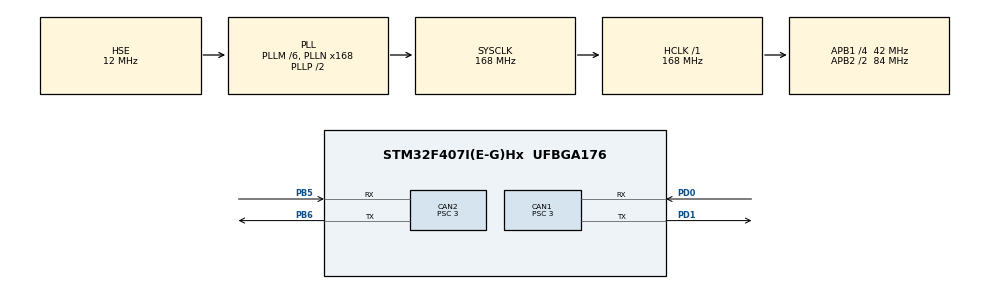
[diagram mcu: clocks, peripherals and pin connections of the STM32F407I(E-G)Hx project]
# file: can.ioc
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CAN1.BS1=CAN_BS1_10TQ
CAN1.BS2=CAN_BS2_3TQ
CAN1.CalculateBaudRate=1000000
CAN1.CalculateTimeQuantum=71.42857142857143
CAN1.Prescaler=3
CAN2.BS1=CAN_BS1_10TQ
CAN2.BS2=CAN_BS2_3TQ
CAN2.CalculateBaudRate=1000000
CAN2.CalculateTimeQuantum=71.42857142857143
CAN2.Prescaler=3
FREERTOS.Tasks01=defaultTask,0,128,StartDefaultTask,Default,NULL,Dynamic,NULL,NULL;CHASSIS_TASK,0,512,Chassis_Task,Default,NULL,Dynamic,NULL,NULL;XY,0,128,xy,Default,NULL,Dynamic,NULL,NULL;TD_TASK,0,128,TD_task,Default,NULL,Dynamic,NULL,NULL
Mcu.Family=STM32F4
Mcu.Name=STM32F407I(E-G)Hx
Mcu.Package=UFBGA176
NVIC.CAN1_RX0_IRQn=true\:5\:0\:false\:false\:true\:true\:true\:true\:true
NVIC.CAN1_TX_IRQn=true\:5\:0\:false\:false\:true\:true\:true\:true\:true
NVIC.CAN2_RX0_IRQn=true\:5\:0\:false\:false\:true\:true\:true\:true\:true
NVIC.CAN2_TX_IRQn=true\:5\:0\:false\:false\:true\:true\:true\:true\:true
NVIC.PriorityGroup=NVIC_PRIORITYGROUP_4
PA13.Mode=Serial_Wire
PA13.Signal=SYS_JTMS-SWDIO
PA14.Mode=Serial_Wire
PA14.Signal=SYS_JTCK-SWCLK
PB5.Mode=CAN_Activate
PB5.Signal=CAN2_RX
PB6.Mode=CAN_Activate
PB6.Signal=CAN2_TX
PD0.Mode=CAN_Activate
PD0.Signal=CAN1_RX
PD1.Mode=CAN_Activate
PD1.Signal=CAN1_TX
PH0-OSC_IN.Mode=HSE-External-Oscillator
PH0-OSC_IN.Signal=RCC_OSC_IN
PH1-OSC_OUT.Mode=HSE-External-Oscillator
PH1-OSC_OUT.Signal=RCC_OSC_OUT
ProjectManager.HeapSize=0x200
ProjectManager.StackSize=0x400
ProjectManager.TargetToolchain=MDK-ARM V5
RCC.48MHZClocksFreq_Value=84000000
RCC.AHBFreq_Value=168000000
RCC.APB1CLKDivider=RCC_HCLK_DIV4
RCC.APB1Freq_Value=42000000
RCC.APB1TimFreq_Value=84000000
RCC.APB2CLKDivider=RCC_HCLK_DIV2
RCC.APB2Freq_Value=84000000
RCC.APB2TimFreq_Value=168000000
RCC.CortexFreq_Value=168000000
RCC.HCLKFreq_Value=168000000
RCC.HSE_VALUE=12000000
RCC.HSI_VALUE=16000000
RCC.LSE_VALUE=32768
RCC.PLLM=6
RCC.PLLN=168
RCC.PLLSourceVirtual=RCC_PLLSOURCE_HSE
RCC.SYSCLKFreq_VALUE=168000000
RCC.SYSCLKSource=RCC_SYSCLKSOURCE_PLLCLK
RCC.VCOOutputFreq_Value=336000000
VP_FREERTOS_VS_CMSIS_V1.Mode=CMSIS_V1
board=custom

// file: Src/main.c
/* USER CODE BEGIN Header */
/**
  ******************************************************************************
  * @file           : main.c
  * @brief          : Main program body
  ******************************************************************************
  * @attention
  *
  * <h2><center>&copy; Copyright (c) 2019 STMicroelectronics.
  * All rights reserved.</center></h2>
  *
  * This software component is licensed by ST under BSD 3-Clause license,
  * the "License"; You may not use this file except in compliance with the
  * License. You may obtain a copy of the License at:
  *                        opensource.org/licenses/BSD-3-Clause
  *
  ******************************************************************************
  */
/* USER CODE END Header */
#include "main.h"
#include "cmsis_os.h"
#include "can.h"
#include "gpio.h"

/* USER CODE BEGIN Includes */
#include "bsp_can.h"
#include "CAN_receive.h"
/* USER CODE END Includes */

void SystemClock_Config(void);
void MX_FREERTOS_Init(void);

int main(void)
{

  /* MCU Configuration--------------------------------------------------------*/

  /* Reset of all peripherals, Initializes the Flash interface and the Systick. */
  HAL_Init();

  /* Configure the system clock */
  SystemClock_Config();

  /* Initialize all configured peripherals */
  MX_GPIO_Init();
  MX_CAN1_Init();
  MX_CAN2_Init();
  /* USER CODE BEGIN 2 */
    can_filter_init();
  /* USER CODE END 2 */

  /* Call init function for freertos objects (in cmsis_os2.c) */
  MX_FREERTOS_Init();

  /* Start scheduler */
  osKernelStart();

  /* We should never get here as control is now taken by the scheduler */

  /* Infinite loop */
  while (1)
  {

  }
}

void SystemClock_Config(void)
{
  RCC_OscInitTypeDef RCC_OscInitStruct = {0};
  RCC_ClkInitTypeDef RCC_ClkInitStruct = {0};

  /** Configure the main internal regulator output voltage
  */
  __HAL_RCC_PWR_CLK_ENABLE();
  __HAL_PWR_VOLTAGESCALING_CONFIG(PWR_REGULATOR_VOLTAGE_SCALE1);

  /** Initializes the RCC Oscillators according to the specified parameters
  * in the RCC_OscInitTypeDef structure.
  */
  RCC_OscInitStruct.OscillatorType = RCC_OSCILLATORTYPE_HSE;
  RCC_OscInitStruct.HSEState = RCC_HSE_ON;
  RCC_OscInitStruct.PLL.PLLState = RCC_PLL_ON;
  RCC_OscInitStruct.PLL.PLLSource = RCC_PLLSOURCE_HSE;
  RCC_OscInitStruct.PLL.PLLM = 6;
  RCC_OscInitStruct.PLL.PLLN = 168;
  RCC_OscInitStruct.PLL.PLLP = RCC_PLLP_DIV2;
  RCC_OscInitStruct.PLL.PLLQ = 4;
  if (HAL_RCC_OscConfig(&RCC_OscInitStruct) != HAL_OK)
  {
    Error_Handler();
  }

  /** Initializes the CPU, AHB and APB buses clocks
  */
  RCC_ClkInitStruct.ClockType = RCC_CLOCKTYPE_HCLK|RCC_CLOCKTYPE_SYSCLK
                              |RCC_CLOCKTYPE_PCLK1|RCC_CLOCKTYPE_PCLK2;
  RCC_ClkInitStruct.SYSCLKSource = RCC_SYSCLKSOURCE_PLLCLK;
  RCC_ClkInitStruct.AHBCLKDivider = RCC_SYSCLK_DIV1;
  RCC_ClkInitStruct.APB1CLKDivider = RCC_HCLK_DIV4;
  RCC_ClkInitStruct.APB2CLKDivider = RCC_HCLK_DIV2;

  if (HAL_RCC_ClockConfig(&RCC_ClkInitStruct, FLASH_LATENCY_5) != HAL_OK)
  {
    Error_Handler();
  }
}

void Error_Handler(void)
{
}

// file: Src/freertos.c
/* USER CODE BEGIN Header */
/**
 ******************************************************************************
 * File Name          : freertos.c
 * Description        : Code for freertos applications
 ******************************************************************************
 * @attention
 *
 * Copyright (c) 2025 STMicroelectronics.
 * All rights reserved.
 *
 * This software is licensed under terms that can be found in the LICENSE file
 * in the root directory of this software component.
 * If no LICENSE file comes with this software, it is provided AS-IS.
 *
 ******************************************************************************
 */
/* USER CODE END Header */

#include "FreeRTOS.h"
#include "task.h"
#include "main.h"
#include "cmsis_os.h"

/* USER CODE BEGIN Includes */
#include "Chassis_task.h"
#include "TD.h"
/* USER CODE END Includes */

osThreadId defaultTaskHandle;
osThreadId CHASSIS_TASKHandle;
osThreadId XYHandle;
osThreadId TD_TASKHandle;

void StartDefaultTask(void const *argument);
void Chassis_Task(void const *argument);
void xy(void const *argument);
void TD_task(void const *argument);

void MX_FREERTOS_Init(void); /* (MISRA C 2004 rule 8.1) */

/* GetIdleTaskMemory prototype (linked to static allocation support) */
void vApplicationGetIdleTaskMemory(StaticTask_t **ppxIdleTaskTCBBuffer, StackType_t **ppxIdleTaskStackBuffer, uint32_t *pulIdleTaskStackSize);

/* USER CODE BEGIN GET_IDLE_TASK_MEMORY */
static StaticTask_t xIdleTaskTCBBuffer;
static StackType_t xIdleStack[configMINIMAL_STACK_SIZE];

void vApplicationGetIdleTaskMemory(StaticTask_t **ppxIdleTaskTCBBuffer, StackType_t **ppxIdleTaskStackBuffer, uint32_t *pulIdleTaskStackSize)
{
  *ppxIdleTaskTCBBuffer = &xIdleTaskTCBBuffer;
  *ppxIdleTaskStackBuffer = &xIdleStack[0];
  *pulIdleTaskStackSize = configMINIMAL_STACK_SIZE;
  /* place for user code */
}
/* USER CODE END GET_IDLE_TASK_MEMORY */

void MX_FREERTOS_Init(void)
{

  /* Create the thread(s) */
  /* definition and creation of defaultTask */
  osThreadDef(defaultTask, StartDefaultTask, osPriorityNormal, 0, 128);
  defaultTaskHandle = osThreadCreate(osThread(defaultTask), NULL);

  /* definition and creation of CHASSIS_TASK */
  osThreadDef(CHASSIS_TASK, Chassis_Task, osPriorityNormal, 0, 512);
  CHASSIS_TASKHandle = osThreadCreate(osThread(CHASSIS_TASK), NULL);

  /* definition and creation of XY */
  osThreadDef(XY, xy, osPriorityNormal, 0, 128);
  XYHandle = osThreadCreate(osThread(XY), NULL);

  /* definition and creation of TD_TASK */
  osThreadDef(TD_TASK, TD_task, osPriorityNormal, 0, 128);
  TD_TASKHandle = osThreadCreate(osThread(TD_TASK), NULL);

}

void StartDefaultTask(void const *argument)
{
  for (;;)
  {
    osDelay(1);
  }
}

void Chassis_Task(void const *argument)
{
  /* USER CODE BEGIN Chassis_Task */
   chassis_init();
  /* Infinite loop */
  for (;;)
  {
     Chassis_Task_os();
    osDelay(1);
  }
  /* USER CODE END Chassis_Task */
}

void xy(void const *argument)
{
  /* USER CODE BEGIN xy */
  // XY_pid_init();
  /* Infinite loop */
  for (;;)
  {
    // XY_task();
    osDelay(1);
  }
  /* USER CODE END xy */
}

void TD_task(void const *argument)
{
  /* USER CODE BEGIN TD_task */
//  TD_INIT();
  /* Infinite loop */
  for (;;)
  {
//    td_task();
    osDelay(1);
  }
  /* USER CODE END TD_task */
}
